VERSION "ACC_ADAS_TC011 1.0"

NS_ :

BS_:

BU_: ACC

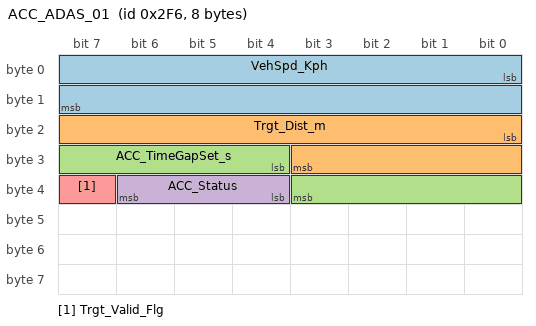
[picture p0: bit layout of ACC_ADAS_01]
BO_ 758 ACC_ADAS_01: 8 ACC
 SG_ VehSpd_Kph : 0|16@1+ (0.01,0) [0|655.35] "km/h" Vector__XXX
 SG_ Trgt_Dist_m : 16|12@1+ (0.05,0) [0|204.75] "m" Vector__XXX
 SG_ ACC_TimeGapSet_s : 28|8@1+ (0.01,0) [0|2.55] "s" Vector__XXX
 SG_ ACC_Status : 36|3@1+ (1,0) [0|7] "1" Vector__XXX
 SG_ Trgt_Valid_Flg : 39|1@1+ (1,0) [0|1] "1" Vector__XXX
